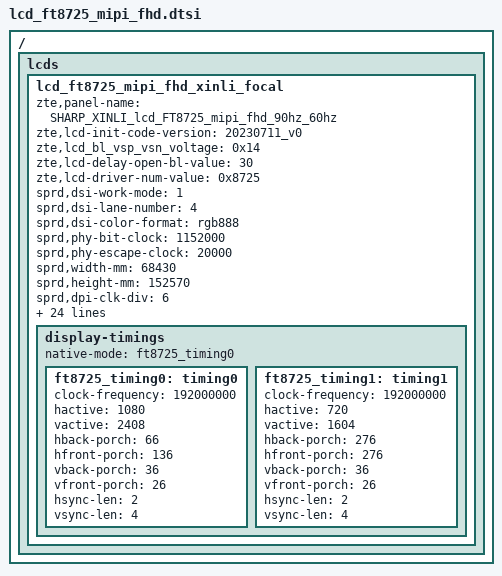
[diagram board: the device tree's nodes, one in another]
// SPDX-License-Identifier: GPL-2.0-only
/*
 * Unisoc ili9881c Truly LCD config DTS file
 *
 * Copyright (C) 2021, Unisoc Inc.
 */
/ {
	fragment {
		target-path = "/";
		__overlay__ {
			lcds {
				lcd_ft8725_mipi_fhd_xinli_focal: lcd_ft8725_mipi_fhd_xinli_focal {
					zte,panel-name = "SHARP_XINLI_lcd_FT8725_mipi_fhd_90hz_60hz";
					zte,lcd-init-code-version = "20230711_v0";
					zte,lcd_bl_vsp_vsn_voltage = <0x14>;
					zte,lcd-delay-open-bl-value = <30>;
					zte,lcd-driver-num-value = <0x8725>;
					sprd,dsi-work-mode = <1>;
					sprd,dsi-lane-number = <4>;
					sprd,dsi-color-format = "rgb888";

					sprd,phy-bit-clock = <1152000>;	/* kbps */
					sprd,phy-escape-clock = <20000>;/* kHz */

					sprd,width-mm = <68430>;/*zte mod for 6.58*/
					sprd,height-mm = <152570>;/*zte mod for 6.58*/
					sprd,dpi-clk-div = <6>;
					sprd,video-lp-cmd-enable = <1>;
					sprd,hporch-lp-disable = <1>;
					lcd-glass = "SHARP";
					lcd-module = "XINLI";
					lcd-name = "FT8725S";

					sprd,esd-check-enable = <1>;/* 0:close , 1:open */
					sprd,esd-check-mode = <0>;/* 0:REG ,1:TE  */
					sprd,esd-check-period = <1000>;
					sprd,esd-check-register = <0x0A>;
					sprd,esd-check-value = <0x9C>;

					sprd,reset-on-sequence = <1 10>, <0 10>, <1 50>;
					sprd,reset-off-sequence = <0 20>;

					//sprd,use-dcs-write;
sprd,initial-command = [
29 00 00 02 00 00
29 00 00 04 ff 87 25 01
29 00 00 02 00 80
29 00 00 03 ff 87 25
29 00 00 02 00 0e
29 00 00 03 f3 80 ff
29 00 00 02 00 a3
29 00 00 03 b3 09 68
29 00 00 02 00 80
29 00 00 07 c0 00 5d 00 2e 00 14
29 00 00 02 00 90
29 00 00 07 c0 00 9d 00 2e 00 14
29 00 00 02 00 a0
29 00 00 07 c0 00 9d 00 2e 00 14
29 00 00 02 00 b0
29 00 00 06 c0 00 ba 00 2e 14
29 00 00 02 00 c1
29 00 00 09 c0 00 8b 00 7a 00 5d 00 b8
29 00 00 02 00 70
29 00 00 07 c0 00 9d 00 2e 00 14
29 00 00 02 00 a3
29 00 00 07 c1 00 4d 00 4a 00 02
29 00 00 02 00 b7
29 00 00 03 c1 00 4d
29 00 00 02 00 7b
29 00 00 03 ce ff ff
29 00 00 02 00 80
29 00 00 11 ce 01 81 ff ff 00 85 00 85 00 c8 00 c8 00 c8 00 c8
29 00 00 02 00 90
29 00 00 10 ce 00 a7 10 43 00 a7 80 ff ff 00 07 6c 09 0f 0f
29 00 00 02 00 a0
29 00 00 04 ce 00 00 00
29 00 00 02 00 b0
29 00 00 04 ce 22 00 00
29 00 00 02 00 d1
29 00 00 08 ce 00 00 01 00 00 00 00
29 00 00 02 00 e1
29 00 00 0c ce 0a 03 cc 03 cc 03 cc 00 00 00 00
29 00 00 02 00 f1
29 00 00 0a ce 15 15 15 01 21 00 ed 00 ed
29 00 00 02 00 b0
29 00 00 05 cf 00 00 c3 c7
29 00 00 02 00 b5
29 00 00 05 cf 05 05 73 77
29 00 00 02 00 c0
29 00 00 05 cf 09 09 63 67
29 00 00 02 00 c5
29 00 00 05 cf 09 09 69 6d
29 00 00 02 00 60
29 00 00 09 cf 00 00 c3 c7 05 05 73 77
29 00 00 02 00 70
29 00 00 09 cf 00 00 c3 c7 05 05 73 77
29 00 00 02 00 d1
29 00 00 0d c1 0b 60 0f dc 1b 15 05 af 07 e5 0d 81
29 00 00 02 00 e1
29 00 00 03 c1 0f dc
29 00 00 02 00 e4
29 00 00 0d cf 09 fa 09 f9 09 f9 09 f9 09 f9 09 f9
29 00 00 02 00 80
29 00 00 03 c1 00 00
29 00 00 02 00 90
29 00 00 02 c1 03
29 00 00 02 00 f5
29 00 00 02 cf 02
29 00 00 02 00 f6
29 00 00 02 cf 3c
29 00 00 02 00 f1
29 00 00 02 cf 3c
29 00 00 02 00 8f
29 00 00 02 c5 20
29 00 00 02 00 80
29 00 00 02 c5 77
29 00 00 02 00 80
29 00 00 09 c2 82 00 01 8f 81 00 01 8f
29 00 00 02 00 a0
29 00 00 10 c2 82 03 00 01 8f 81 04 00 01 8f 80 05 00 01 8f
29 00 00 02 00 b0
29 00 00 10 c2 01 06 00 01 8f 02 06 00 01 8f 03 07 00 01 8f
29 00 00 02 00 c0
29 00 00 0b c2 04 08 00 01 8f 05 09 00 01 8f
29 00 00 02 00 e0
29 00 00 05 c2 77 77 77 77
29 00 00 02 00 e8
29 00 00 09 c2 08 00 00 00 00 00 00 00
29 00 00 02 00 80
29 00 00 11 cb 00 01 00 00 01 01 00 00 00 00 fd 01 03 00 00 fc
29 00 00 02 00 90
29 00 00 11 cb 00 00 00 00 00 00 00 00 00 00 00 fc 00 00 00 00
29 00 00 02 00 a0
29 00 00 09 cb 00 00 00 00 00 00 03 c0
29 00 00 02 00 b0
29 00 00 05 cb 10 50 05 c0
29 00 00 02 00 c0
29 00 00 05 cb 10 50 05 c0
29 00 00 02 00 d5
29 00 00 0c cb 83 00 83 83 00 83 83 00 83 83 00
29 00 00 02 00 e0
29 00 00 0e cb 83 83 00 83 83 00 83 83 00 83 83 00 83
29 00 00 02 00 80
29 00 00 11 cc 22 2c 2c 2c 2c 2c 2c 1e 1d 1c 18 17 16 23 06 0c
29 00 00 02 00 90
29 00 00 09 cc 0a 08 02 29 29 29 29 29
29 00 00 02 00 a0
29 00 00 11 cc 22 2c 2c 2c 2c 2c 2c 1e 1d 1c 18 17 16 23 0d 07
29 00 00 02 00 b0
29 00 00 09 cc 09 0b 03 29 29 29 29 29
29 00 00 02 00 80
29 00 00 11 cd 22 2c 2c 2c 2c 2c 2c 1e 1d 1c 18 17 16 23 07 0d
29 00 00 02 00 90
29 00 00 09 cd 0b 09 03 29 29 29 29 29
29 00 00 02 00 a0
29 00 00 11 cd 22 2c 2c 2c 2c 2c 2c 1e 1d 1c 18 17 16 23 0c 06
29 00 00 02 00 b0
29 00 00 09 cd 08 0a 02 29 29 29 29 29
29 00 00 02 00 86
29 00 00 09 c0 00 00 00 01 11 11 11 04
29 00 00 02 00 96
29 00 00 09 c0 00 00 00 01 11 11 11 04
29 00 00 02 00 a6
29 00 00 09 c0 00 00 00 01 11 11 11 04
29 00 00 02 00 a3
29 00 00 07 ce 00 00 00 01 11 04
29 00 00 02 00 b3
29 00 00 07 ce 00 00 00 01 11 04
29 00 00 02 00 76
29 00 00 09 c0 00 00 00 01 29 29 29 07
29 00 00 02 00 82
29 00 00 03 a7 00 00
29 00 00 02 00 8d
29 00 00 02 a7 00
29 00 00 02 00 8f
29 00 00 02 a7 00
29 00 00 02 00 93
29 00 00 02 c5 33
29 00 00 02 00 97
29 00 00 02 c5 33
29 00 00 02 00 9a
29 00 00 02 c5 19
29 00 00 02 00 9c
29 00 00 02 c5 19
29 00 00 02 00 b6
29 00 00 09 c5 17 17 0a 0a 17 17 0a 0a
29 00 00 02 00 00
29 00 00 03 d8 2e 2e

29 00 00 02 00 a0
29 00 00 02 c3 00
29 00 00 02 00 80
29 00 00 02 a7 03
29 00 00 02 00 b1
29 00 00 02 f5 1f
29 00 00 02 00 cb
29 00 00 02 c0 11
29 00 00 02 00 88
29 00 00 02 c4 08
29 00 00 02 00 9a
29 00 00 02 c4 11
29 00 00 02 00 82
29 00 00 02 f5 01
29 00 00 02 00 93
29 00 00 02 f5 01
29 00 00 02 00 99
29 00 00 02 cf 50
29 00 00 02 00 9c
29 00 00 02 f5 00
29 00 00 02 00 9e
29 00 00 02 f5 00
29 00 00 02 00 b0
29 00 00 07 c5 10 4a 01 1f 4a 00
29 00 00 02 00 e8
29 00 00 02 c0 40

29 00 00 02 00 e0
29 00 00 02 cf 34
29 00 00 02 00 85
29 00 00 02 a7 00
29 00 00 02 00 92
29 00 00 02 c5 00
29 00 00 02 00 a0
29 00 00 02 c5 40
29 00 00 02 00 98
29 00 00 02 c5 24
29 00 00 02 00 a1
29 00 00 02 c5 40
29 00 00 02 00 9d
29 00 00 02 c5 24
29 00 00 02 00 94
29 00 00 02 c5 04
29 00 00 02 00 80
29 00 00 02 b3 22
29 00 00 02 00 b0
29 00 00 02 b3 00
29 00 00 02 00 83
29 00 00 02 b0 63
29 00 00 02 00 93
29 00 00 02 c1 82
29 00 00 02 00 87
29 00 00 03 c5 0a 0a
29 00 00 02 00 81
29 00 00 02 c5 59
29 00 00 02 00 a0
29 00 00 08 b0 00 00 00 00 00 1d 01
29 00 00 02 00 82
29 00 00 03 ce 11 11
29 00 00 02 00 90
29 00 00 02 a7 1d
29 00 00 02 00 f7
29 00 00 02 cf 51
29 00 00 03 1f 5a 5a
29 00 00 02 1c 12
29 00 00 02 00 82
29 00 00 02 b4 06
29 00 00 02 00 a4
29 00 00 02 b3 66
29 00 00 02 00 00
29 00 00 04 ff ff ff ff
29 00 00 02 00 00
29 00 00 04 ff 87 25 01
29 00 00 02 00 80
29 00 00 03 ff 87 25
29 00 00 03 1f 3c 3c
29 00 00 02 1c 02
29 00 00 02 00 f6
29 00 00 02 cf 3c
29 00 00 02 00 82
29 00 00 02 b4 00
29 00 00 02 00 a4
29 00 00 02 b3 68
29 00 00 02 00 F6
29 00 00 02 CF 3C
05 78 00 01 11
05 14 00 01 29
];

zte,initial-command-fps90 = [
29 00 00 02 00 00
29 00 00 04 ff 87 25 01
29 00 00 02 00 80
29 00 00 03 ff 87 25
29 00 00 02 00 0e
29 00 00 03 f3 80 ff
29 00 00 02 00 a3
29 00 00 03 b3 09 68
29 00 00 02 00 80
29 00 00 07 c0 00 5d 00 2e 00 14
29 00 00 02 00 90
29 00 00 07 c0 00 9d 00 2e 00 14
29 00 00 02 00 a0
29 00 00 07 c0 00 9d 00 2e 00 14
29 00 00 02 00 b0
29 00 00 06 c0 00 ba 00 2e 14
29 00 00 02 00 c1
29 00 00 09 c0 00 8b 00 7a 00 5d 00 b8
29 00 00 02 00 70
29 00 00 07 c0 00 9d 00 2e 00 14
29 00 00 02 00 a3
29 00 00 07 c1 00 4d 00 4a 00 02
29 00 00 02 00 b7
29 00 00 03 c1 00 4d
29 00 00 02 00 7b
29 00 00 03 ce ff ff
29 00 00 02 00 80
29 00 00 11 ce 01 81 ff ff 00 85 00 85 00 c8 00 c8 00 c8 00 c8
29 00 00 02 00 90
29 00 00 10 ce 00 a7 10 43 00 a7 80 ff ff 00 07 6c 09 0f 0f
29 00 00 02 00 a0
29 00 00 04 ce 00 00 00
29 00 00 02 00 b0
29 00 00 04 ce 22 00 00
29 00 00 02 00 d1
29 00 00 08 ce 00 00 01 00 00 00 00
29 00 00 02 00 e1
29 00 00 0c ce 0a 03 cc 03 cc 03 cc 00 00 00 00
29 00 00 02 00 f1
29 00 00 0a ce 15 15 15 01 21 00 ed 00 ed
29 00 00 02 00 b0
29 00 00 05 cf 00 00 c3 c7
29 00 00 02 00 b5
29 00 00 05 cf 05 05 73 77
29 00 00 02 00 c0
29 00 00 05 cf 09 09 63 67
29 00 00 02 00 c5
29 00 00 05 cf 09 09 69 6d
29 00 00 02 00 60
29 00 00 09 cf 00 00 c3 c7 05 05 73 77
29 00 00 02 00 70
29 00 00 09 cf 00 00 c3 c7 05 05 73 77
29 00 00 02 00 d1
29 00 00 0d c1 0b 60 0f dc 1b 15 05 af 07 e5 0d 81
29 00 00 02 00 e1
29 00 00 03 c1 0f dc
29 00 00 02 00 e4
29 00 00 0d cf 09 fa 09 f9 09 f9 09 f9 09 f9 09 f9
29 00 00 02 00 80
29 00 00 03 c1 00 00
29 00 00 02 00 90
29 00 00 02 c1 03
29 00 00 02 00 f5
29 00 00 02 cf 02
29 00 00 02 00 f6
29 00 00 02 cf 3c
29 00 00 02 00 f1
29 00 00 02 cf 3c
29 00 00 02 00 8f
29 00 00 02 c5 20
29 00 00 02 00 80
29 00 00 02 c5 77
29 00 00 02 00 80
29 00 00 09 c2 82 00 01 8f 81 00 01 8f
29 00 00 02 00 a0
29 00 00 10 c2 82 03 00 01 8f 81 04 00 01 8f 80 05 00 01 8f
29 00 00 02 00 b0
29 00 00 10 c2 01 06 00 01 8f 02 06 00 01 8f 03 07 00 01 8f
29 00 00 02 00 c0
29 00 00 0b c2 04 08 00 01 8f 05 09 00 01 8f
29 00 00 02 00 e0
29 00 00 05 c2 77 77 77 77
29 00 00 02 00 e8
29 00 00 09 c2 08 00 00 00 00 00 00 00
29 00 00 02 00 80
29 00 00 11 cb 00 01 00 00 01 01 00 00 00 00 fd 01 03 00 00 fc
29 00 00 02 00 90
29 00 00 11 cb 00 00 00 00 00 00 00 00 00 00 00 fc 00 00 00 00
29 00 00 02 00 a0
29 00 00 09 cb 00 00 00 00 00 00 03 c0
29 00 00 02 00 b0
29 00 00 05 cb 10 50 05 c0
29 00 00 02 00 c0
29 00 00 05 cb 10 50 05 c0
29 00 00 02 00 d5
29 00 00 0c cb 83 00 83 83 00 83 83 00 83 83 00
29 00 00 02 00 e0
29 00 00 0e cb 83 83 00 83 83 00 83 83 00 83 83 00 83
29 00 00 02 00 80
29 00 00 11 cc 22 2c 2c 2c 2c 2c 2c 1e 1d 1c 18 17 16 23 06 0c
29 00 00 02 00 90
29 00 00 09 cc 0a 08 02 29 29 29 29 29
29 00 00 02 00 a0
29 00 00 11 cc 22 2c 2c 2c 2c 2c 2c 1e 1d 1c 18 17 16 23 0d 07
29 00 00 02 00 b0
29 00 00 09 cc 09 0b 03 29 29 29 29 29
29 00 00 02 00 80
29 00 00 11 cd 22 2c 2c 2c 2c 2c 2c 1e 1d 1c 18 17 16 23 07 0d
29 00 00 02 00 90
29 00 00 09 cd 0b 09 03 29 29 29 29 29
29 00 00 02 00 a0
29 00 00 11 cd 22 2c 2c 2c 2c 2c 2c 1e 1d 1c 18 17 16 23 0c 06
29 00 00 02 00 b0
29 00 00 09 cd 08 0a 02 29 29 29 29 29
29 00 00 02 00 86
29 00 00 09 c0 00 00 00 01 11 11 11 04
29 00 00 02 00 96
29 00 00 09 c0 00 00 00 01 11 11 11 04
29 00 00 02 00 a6
29 00 00 09 c0 00 00 00 01 11 11 11 04
29 00 00 02 00 a3
29 00 00 07 ce 00 00 00 01 11 04
29 00 00 02 00 b3
29 00 00 07 ce 00 00 00 01 11 04
29 00 00 02 00 76
29 00 00 09 c0 00 00 00 01 29 29 29 07
29 00 00 02 00 82
29 00 00 03 a7 00 00
29 00 00 02 00 8d
29 00 00 02 a7 00
29 00 00 02 00 8f
29 00 00 02 a7 00
29 00 00 02 00 93
29 00 00 02 c5 33
29 00 00 02 00 97
29 00 00 02 c5 33
29 00 00 02 00 9a
29 00 00 02 c5 19
29 00 00 02 00 9c
29 00 00 02 c5 19
29 00 00 02 00 b6
29 00 00 09 c5 17 17 0a 0a 17 17 0a 0a
29 00 00 02 00 00
29 00 00 03 d8 2e 2e

29 00 00 02 00 a0
29 00 00 02 c3 00
29 00 00 02 00 80
29 00 00 02 a7 03
29 00 00 02 00 b1
29 00 00 02 f5 1f
29 00 00 02 00 cb
29 00 00 02 c0 11
29 00 00 02 00 88
29 00 00 02 c4 08
29 00 00 02 00 9a
29 00 00 02 c4 11
29 00 00 02 00 82
29 00 00 02 f5 01
29 00 00 02 00 93
29 00 00 02 f5 01
29 00 00 02 00 99
29 00 00 02 cf 50
29 00 00 02 00 9c
29 00 00 02 f5 00
29 00 00 02 00 9e
29 00 00 02 f5 00
29 00 00 02 00 b0
29 00 00 07 c5 10 4a 01 1f 4a 00
29 00 00 02 00 e8
29 00 00 02 c0 40

29 00 00 02 00 e0
29 00 00 02 cf 34
29 00 00 02 00 85
29 00 00 02 a7 00
29 00 00 02 00 92
29 00 00 02 c5 00
29 00 00 02 00 a0
29 00 00 02 c5 40
29 00 00 02 00 98
29 00 00 02 c5 24
29 00 00 02 00 a1
29 00 00 02 c5 40
29 00 00 02 00 9d
29 00 00 02 c5 24
29 00 00 02 00 94
29 00 00 02 c5 04
29 00 00 02 00 80
29 00 00 02 b3 22
29 00 00 02 00 b0
29 00 00 02 b3 00
29 00 00 02 00 83
29 00 00 02 b0 63
29 00 00 02 00 93
29 00 00 02 c1 82
29 00 00 02 00 87
29 00 00 03 c5 0a 0a
29 00 00 02 00 81
29 00 00 02 c5 59
29 00 00 02 00 a0
29 00 00 08 b0 00 00 00 00 00 1d 01
29 00 00 02 00 82
29 00 00 03 ce 11 11
29 00 00 02 00 90
29 00 00 02 a7 1d
29 00 00 02 00 f7
29 00 00 02 cf 51
29 00 00 03 1f 5a 5a
29 00 00 02 1c 12
29 00 00 02 00 82
29 00 00 02 b4 06
29 00 00 02 00 a4
29 00 00 02 b3 66
29 00 00 02 00 00
29 00 00 04 ff ff ff ff
29 00 00 02 00 00
29 00 00 04 ff 87 25 01
29 00 00 02 00 80
29 00 00 03 ff 87 25
29 00 00 03 1f 5a 5a
29 00 00 02 00 f6
29 00 00 02 cf 5a
05 78 00 01 11
05 14 00 01 29
];
					sprd,sleep-in-command = [
						05 14 00 01 28
						05 78 00 01 10
						29 00 00 02 00 00
						29 01 00 05 F7 5A A5 95 27
						];
					sprd,sleep-out-command = [
						05 78 00 01 11
						05 14 00 01 29
						];
zte,fps90-to-fps60 = [
29 00 00 02 00 00
29 00 00 04 ff 87 25 01
29 00 00 02 00 80
29 00 00 03 ff 87 25
29 00 00 03 1f 3c 3c
29 00 00 02 00 f6
29 00 00 02 cf 3c
29 00 00 02 36 00
];

zte,fps60-to-fps90 = [
29 00 00 02 00 00
29 00 00 04 ff 87 25 01
29 00 00 02 00 80
29 00 00 03 ff 87 25
29 00 00 03 1f 5a 5a
29 00 00 02 00 f6
29 00 00 02 cf 5a
29 00 00 02 36 00
];

					display-timings {
						native-mode = <&ft8725_timing0>;

						ft8725_timing0:timing0 {/*60Hz FHD*/
							clock-frequency = <192000000>;
							hactive = <1080>;
							vactive = <2408>;
							hback-porch = <66>;
							hfront-porch = <136>;
							vback-porch = <36>;
							vfront-porch = <26>;
							hsync-len = <2>;
							vsync-len = <4>;
						};

						ft8725_timing1:timing1 {/*90Hz HD*/
							clock-frequency = <192000000>;
							hactive = <720>;
							vactive = <1604>;
							hback-porch = <276>;
							hfront-porch = <276>;
							vback-porch = <36>;
							vfront-porch = <26>;
							hsync-len = <2>;
							vsync-len = <4>;
						};

						/*60Hz HD*/
						/*
						ft8725_timing2:timing2 {
							clock-frequency = <192000000>;
							hactive = <720>;
							vactive = <1604>;
							hback-porch = <276>;
							hfront-porch = <276>;
							vback-porch = <36>;
							vfront-porch = <860>;
							hsync-len = <2>;
							vsync-len = <4>;
						};
						*/
					};
				};
			};
		};
	};
};
